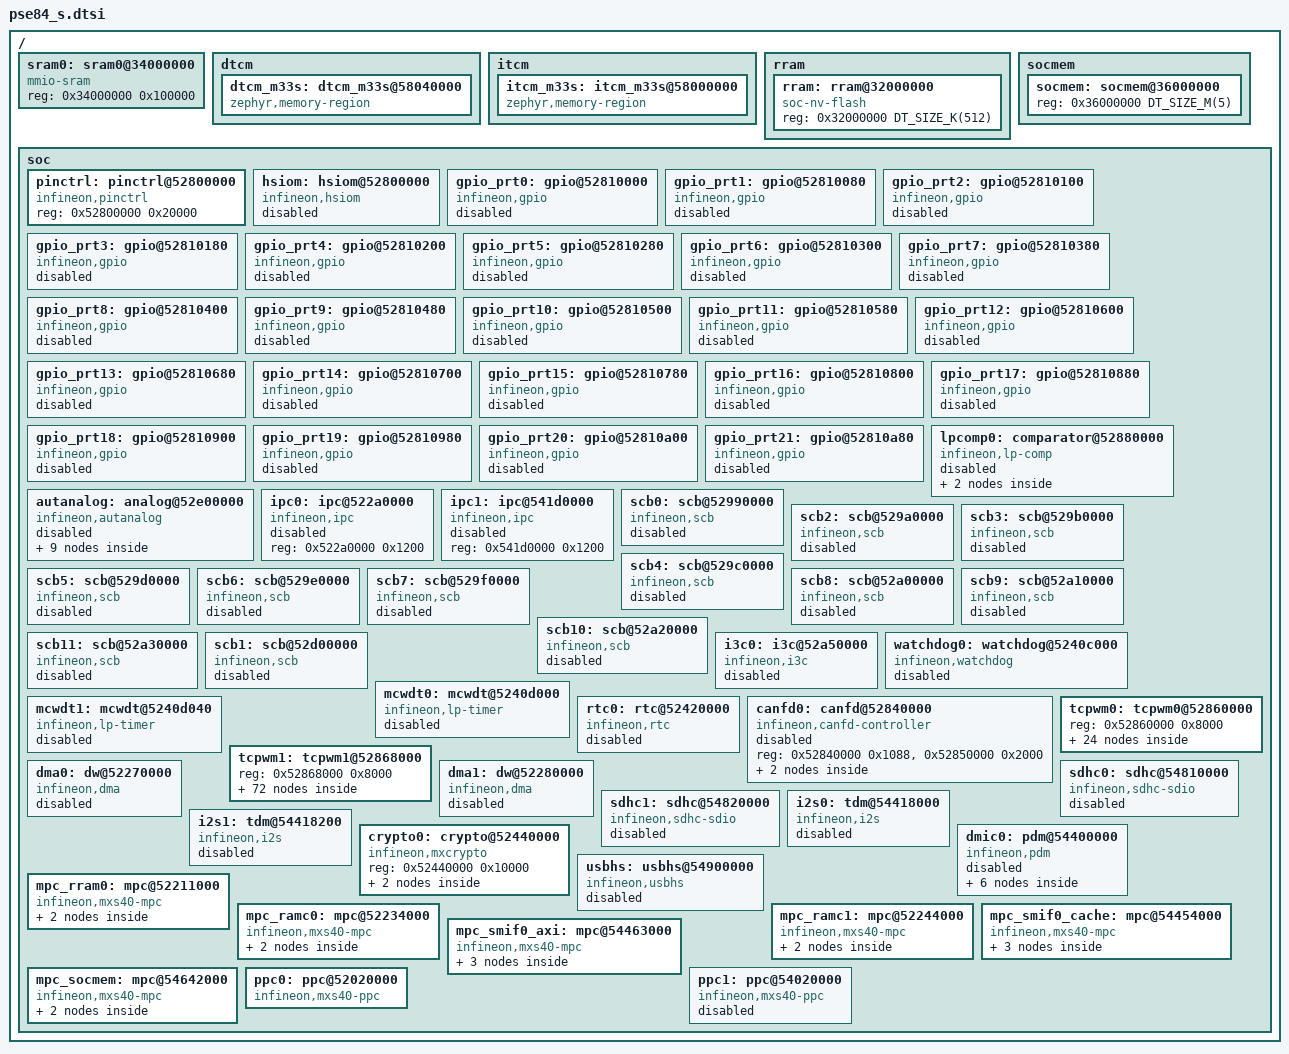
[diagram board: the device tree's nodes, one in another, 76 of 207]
/*
 * SPDX-FileCopyrightText: <text>Copyright (c) 2026 Infineon Technologies AG,
 * or an affiliate of Infineon Technologies AG. All rights reserved.</text>
 *
 * SPDX-License-Identifier: Apache-2.0
 */

#include <mem.h>
#include <zephyr/dt-bindings/ppc/infineon-edge-ppc.h>

/ {
	sram0: sram0@34000000 {
		compatible = "mmio-sram";
		reg = <0x34000000 0x100000>;
	};

	dtcm {
		#address-cells = <1>;
		#size-cells = <1>;

		dtcm_m33s: dtcm_m33s@58040000 {
			compatible = "zephyr,memory-region", "arm,dtcm";
			reg = <0x58040000 DT_SIZE_K(256)>;
			zephyr,memory-region = "DTCM";
		};
	};

	itcm {
		#address-cells = <1>;
		#size-cells = <1>;

		itcm_m33s: itcm_m33s@58000000 {
			compatible = "zephyr,memory-region", "arm,itcm";
			reg = <0x58000000 DT_SIZE_K(256)>;
			zephyr,memory-region = "ITCM";
		};
	};

	rram {
		#address-cells = <1>;
		#size-cells = <1>;

		rram: rram@32000000 {
			compatible = "soc-nv-flash";
			reg = <0x32000000 DT_SIZE_K(512)>;
		};
	};

	socmem {
		#address-cells = <1>;
		#size-cells = <1>;

		socmem: socmem@36000000 {
			reg = <0x36000000 DT_SIZE_M(5)>;
		};
	};

	soc {
		pinctrl: pinctrl@52800000 {
			compatible = "infineon,pinctrl";
			reg = <0x52800000 0x20000>;
		};

		hsiom: hsiom@52800000 {
			compatible = "infineon,hsiom";
			reg = <0x52800000 0x4000>;
			interrupts = <42 4>, <40 4>;
			status = "disabled";
		};

		gpio_prt0: gpio@52810000 {
			compatible = "infineon,gpio";
			reg = <0x52810000 0x80>;
			interrupts = <20 4>;
			gpio-controller;
			ngpios = <2>;
			status = "disabled";
			wakeup-source;
			#gpio-cells = <2>;
		};

		gpio_prt1: gpio@52810080 {
			compatible = "infineon,gpio";
			reg = <0x52810080 0x80>;
			gpio-controller;
			ngpios = <8>;
			status = "disabled";
			#gpio-cells = <2>;
		};

		gpio_prt2: gpio@52810100 {
			compatible = "infineon,gpio";
			reg = <0x52810100 0x80>;
			interrupts = <21 4>;
			gpio-controller;
			ngpios = <1>;
			status = "disabled";
			wakeup-source;
			#gpio-cells = <2>;
		};

		gpio_prt3: gpio@52810180 {
			compatible = "infineon,gpio";
			reg = <0x52810180 0x80>;
			interrupts = <22 4>;
			gpio-controller;
			ngpios = <2>;
			status = "disabled";
			wakeup-source;
			#gpio-cells = <2>;
		};

		gpio_prt4: gpio@52810200 {
			compatible = "infineon,gpio";
			reg = <0x52810200 0x80>;
			gpio-controller;
			ngpios = <8>;
			status = "disabled";
			#gpio-cells = <2>;
		};

		gpio_prt5: gpio@52810280 {
			compatible = "infineon,gpio";
			reg = <0x52810280 0x80>;
			interrupts = <23 4>;
			gpio-controller;
			ngpios = <1>;
			status = "disabled";
			wakeup-source;
			#gpio-cells = <2>;
		};

		gpio_prt6: gpio@52810300 {
			compatible = "infineon,gpio";
			reg = <0x52810300 0x80>;
			interrupts = <24 4>;
			gpio-controller;
			ngpios = <8>;
			status = "disabled";
			wakeup-source;
			#gpio-cells = <2>;
		};

		gpio_prt7: gpio@52810380 {
			compatible = "infineon,gpio";
			reg = <0x52810380 0x80>;
			interrupts = <25 4>;
			gpio-controller;
			ngpios = <8>;
			status = "disabled";
			wakeup-source;
			#gpio-cells = <2>;
		};

		gpio_prt8: gpio@52810400 {
			compatible = "infineon,gpio";
			reg = <0x52810400 0x80>;
			interrupts = <26 4>;
			gpio-controller;
			ngpios = <8>;
			status = "disabled";
			wakeup-source;
			#gpio-cells = <2>;
		};

		gpio_prt9: gpio@52810480 {
			compatible = "infineon,gpio";
			reg = <0x52810480 0x80>;
			interrupts = <27 4>;
			gpio-controller;
			ngpios = <4>;
			status = "disabled";
			wakeup-source;
			#gpio-cells = <2>;
		};

		gpio_prt10: gpio@52810500 {
			compatible = "infineon,gpio";
			reg = <0x52810500 0x80>;
			interrupts = <28 4>;
			gpio-controller;
			ngpios = <8>;
			status = "disabled";
			wakeup-source;
			#gpio-cells = <2>;
		};

		gpio_prt11: gpio@52810580 {
			compatible = "infineon,gpio";
			reg = <0x52810580 0x80>;
			interrupts = <29 4>;
			gpio-controller;
			ngpios = <8>;
			status = "disabled";
			wakeup-source;
			#gpio-cells = <2>;
		};

		gpio_prt12: gpio@52810600 {
			compatible = "infineon,gpio";
			reg = <0x52810600 0x80>;
			interrupts = <30 4>;
			gpio-controller;
			ngpios = <6>;
			status = "disabled";
			wakeup-source;
			#gpio-cells = <2>;
		};

		gpio_prt13: gpio@52810680 {
			compatible = "infineon,gpio";
			reg = <0x52810680 0x80>;
			interrupts = <31 4>;
			gpio-controller;
			ngpios = <8>;
			status = "disabled";
			wakeup-source;
			#gpio-cells = <2>;
		};

		gpio_prt14: gpio@52810700 {
			compatible = "infineon,gpio";
			reg = <0x52810700 0x80>;
			interrupts = <32 4>;
			gpio-controller;
			ngpios = <8>;
			status = "disabled";
			wakeup-source;
			#gpio-cells = <2>;
		};

		gpio_prt15: gpio@52810780 {
			compatible = "infineon,gpio";
			reg = <0x52810780 0x80>;
			interrupts = <33 4>;
			gpio-controller;
			ngpios = <8>;
			status = "disabled";
			wakeup-source;
			#gpio-cells = <2>;
		};

		gpio_prt16: gpio@52810800 {
			compatible = "infineon,gpio";
			reg = <0x52810800 0x80>;
			interrupts = <34 4>;
			gpio-controller;
			ngpios = <8>;
			status = "disabled";
			wakeup-source;
			#gpio-cells = <2>;
		};

		gpio_prt17: gpio@52810880 {
			compatible = "infineon,gpio";
			reg = <0x52810880 0x80>;
			interrupts = <35 4>;
			gpio-controller;
			ngpios = <8>;
			status = "disabled";
			wakeup-source;
			#gpio-cells = <2>;
		};

		gpio_prt18: gpio@52810900 {
			compatible = "infineon,gpio";
			reg = <0x52810900 0x80>;
			interrupts = <36 4>;
			gpio-controller;
			ngpios = <2>;
			status = "disabled";
			wakeup-source;
			#gpio-cells = <2>;
		};

		gpio_prt19: gpio@52810980 {
			compatible = "infineon,gpio";
			reg = <0x52810980 0x80>;
			interrupts = <37 4>;
			gpio-controller;
			ngpios = <2>;
			status = "disabled";
			wakeup-source;
			#gpio-cells = <2>;
		};

		gpio_prt20: gpio@52810a00 {
			compatible = "infineon,gpio";
			reg = <0x52810a00 0x80>;
			interrupts = <38 4>;
			gpio-controller;
			ngpios = <8>;
			status = "disabled";
			wakeup-source;
			#gpio-cells = <2>;
		};

		gpio_prt21: gpio@52810a80 {
			compatible = "infineon,gpio";
			reg = <0x52810a80 0x80>;
			interrupts = <39 4>;
			gpio-controller;
			ngpios = <8>;
			status = "disabled";
			wakeup-source;
			#gpio-cells = <2>;
		};

		lpcomp0: comparator@52880000 {
			compatible = "infineon,lp-comp";
			reg = <0x52880000 0x10000>;
			status = "disabled";
			wakeup-source;

			lpcomp0_0: lpcomp0-0 {
				compatible = "infineon,lp-comp-channel";
				channel = <0>;
				status = "disabled";
			};

			lpcomp0_1: lpcomp0-1 {
				compatible = "infineon,lp-comp-channel";
				channel = <1>;
				status = "disabled";
			};
		};

		autanalog: analog@52e00000 {
			compatible = "infineon,autanalog";
			reg = <0x52e00000 0x100000>;
			wakeup-source;
			interrupts = <57 4>, <58 4>;
			interrupt-names = "autanalog", "autanalog_fifo";
			status = "disabled";
			#address-cells = <1>;
			#size-cells = <1>;
			ranges;

			ctb0: ctb0@0 {
				compatible = "infineon,autanalog-ctb";
				reg = <0x0 0x1000>;
				status = "disabled";
				#address-cells = <1>;
				#size-cells = <0>;
			};

			ctb1: ctb1@10000 {
				compatible = "infineon,autanalog-ctb";
				reg = <0x10000 0x1000>;
				status = "disabled";
				#address-cells = <1>;
				#size-cells = <0>;
			};

			ptcomp0: ptcomp@e40000 {
				compatible = "infineon,autanalog-ptcomp";
				reg = <0xe40000 0xf00>;
				status = "disabled";
				#address-cells = <1>;
				#size-cells = <0>;
			};

			dac0: dac0@60000 {
				compatible = "infineon,autanalog-ctdac";
				reg = <0x60000 0x1000>;
				clk-dst = <0x200>;
				status = "disabled";
				#io-channel-cells = <1>;
				#address-cells = <1>;
				#size-cells = <0>;

				/* FW channel (default) */
				channel@f {
					reg = <15>;
					zephyr,resolution = <12>;
				};
			};

			dac1: dac1@70000 {
				compatible = "infineon,autanalog-ctdac";
				reg = <0x70000 0x1000>;
				clk-dst = <0x201>;
				status = "disabled";
				#io-channel-cells = <1>;
				#address-cells = <1>;
				#size-cells = <0>;

				/* FW channel (default): direct value writes via Zephyr DAC API */
				channel@f {
					reg = <15>;
					zephyr,resolution = <12>;
				};
			};

			adc0: adc0@80000 {
				compatible = "infineon,autanalog-sar-adc";
				/* Offset within AutAnalog subsystem */
				reg = <0x80000 0xf20>;
				status = "disabled";
				#io-channel-cells = <1>;
			};

			prb0: prb@e0300 {
				compatible = "infineon,autanalog-prb";
				reg = <0xe0300 0x100>;
				status = "disabled";
				#address-cells = <1>;
				#size-cells = <0>;
			};
		};

		ipc0: ipc@522a0000 {
			compatible = "infineon,ipc";
			reg = <0x522a0000 0x1200>;
			status = "disabled";
			#ipc-config-cells = <3>;
		};

		ipc1: ipc@541d0000 {
			compatible = "infineon,ipc";
			reg = <0x541d0000 0x1200>;
			status = "disabled";
			#ipc-config-cells = <3>;
		};

		scb0: scb@52990000 {
			compatible = "infineon,scb";
			reg = <0x52990000 0xfd0>;
			interrupts = <43 4>;
			clk-dst = <0x100>;
			status = "disabled";
			wakeup-source;
		};

		scb2: scb@529a0000 {
			compatible = "infineon,scb";
			reg = <0x529a0000 0xfd0>;
			interrupts = <143 4>;
			clk-dst = <0x101>;
			status = "disabled";
		};

		scb3: scb@529b0000 {
			compatible = "infineon,scb";
			reg = <0x529b0000 0xfd0>;
			interrupts = <144 4>;
			clk-dst = <0x102>;
			status = "disabled";
		};

		scb4: scb@529c0000 {
			compatible = "infineon,scb";
			reg = <0x529c0000 0xfd0>;
			interrupts = <145 4>;
			clk-dst = <0x103>;
			status = "disabled";
		};

		scb5: scb@529d0000 {
			compatible = "infineon,scb";
			reg = <0x529d0000 0xfd0>;
			interrupts = <146 4>;
			clk-dst = <0x104>;
			status = "disabled";
		};

		scb6: scb@529e0000 {
			compatible = "infineon,scb";
			reg = <0x529e0000 0xfd0>;
			interrupts = <147 4>;
			clk-dst = <0x105>;
			status = "disabled";
		};

		scb7: scb@529f0000 {
			compatible = "infineon,scb";
			reg = <0x529f0000 0xfd0>;
			interrupts = <148 4>;
			clk-dst = <0x106>;
			status = "disabled";
		};

		scb8: scb@52a00000 {
			compatible = "infineon,scb";
			reg = <0x52a00000 0xfd0>;
			interrupts = <149 4>;
			clk-dst = <0x107>;
			status = "disabled";
		};

		scb9: scb@52a10000 {
			compatible = "infineon,scb";
			reg = <0x52a10000 0xfd0>;
			interrupts = <150 4>;
			clk-dst = <0x108>;
			status = "disabled";
		};

		scb10: scb@52a20000 {
			compatible = "infineon,scb";
			reg = <0x52a20000 0xfd0>;
			interrupts = <151 4>;
			clk-dst = <0x109>;
			status = "disabled";
		};

		scb11: scb@52a30000 {
			compatible = "infineon,scb";
			reg = <0x52a30000 0xfd0>;
			interrupts = <152 4>;
			clk-dst = <0x10a>;
			status = "disabled";
		};

		scb1: scb@52d00000 {
			compatible = "infineon,scb";
			reg = <0x52d00000 0xfd0>;
			interrupts = <142 4>;
			clk-dst = <0x800>;
			status = "disabled";
		};

		i3c0: i3c@52a50000 {
			compatible = "infineon,i3c";
			reg = <0x52a50000 0x438>;
			interrupts = <176 4>;
			status = "disabled";
		};

		watchdog0: watchdog@5240c000 {
			compatible = "infineon,watchdog";
			reg = <0x5240c000 0x180>;
			interrupts = <54 4>;
			status = "disabled";
			wakeup-source;
		};

		mcwdt0: mcwdt@5240d000 {
			compatible = "infineon,lp-timer";
			reg = <0x5240d000 0x40>;
			interrupts = <55 4>;
			status = "disabled";
			wakeup-source;
		};

		mcwdt1: mcwdt@5240d040 {
			compatible = "infineon,lp-timer";
			reg = <0x5240d040 0x40>;
			interrupts = <0 4>;
			status = "disabled";
			wakeup-source;
		};

		rtc0: rtc@52420000 {
			compatible = "infineon,rtc";
			reg = <0x52420000 0x1140>;
			interrupts = <56 4>;
			alarms-count = <2>;
			status = "disabled";
			wakeup-source;
		};

		canfd0: canfd@52840000 {
			compatible = "infineon,canfd-controller";
			reg = <0x52840000 0x1088>, <0x52850000 0x2000>;
			reg-names = "wrapper", "mram";
			#address-cells = <1>;
			#size-cells = <1>;
			ranges;
			status = "disabled";

			can0: can@52840000 {
				compatible = "infineon,can";
				reg = <0x52840000 0x200>, <0x52850000 0x1000>;
				reg-names = "m_can", "message_ram";
				clk-dst = <0x10b>;
				status = "disabled";
				bosch,mram-cfg = <0x0 15 15 16 0 0 15 15>;
				interrupts = <106 4>, <107 4>;
				interrupt-names = "int0", "int1";
			};

			can1: can@52840200 {
				compatible = "infineon,can";
				reg = <0x52840200 0x200>, <0x52850000 0x2000>;
				reg-names = "m_can", "message_ram";
				clk-dst = <0x10c>;
				status = "disabled";
				bosch,mram-cfg = <0x1000 15 15 16 0 0 15 15>;
				interrupts = <108 4>, <109 4>;
				interrupt-names = "int0", "int1";
			};
		};

		tcpwm0: tcpwm0@52860000 {
			reg = <0x52860000 0x8000>;
			#address-cells = <1>;
			#size-cells = <1>;

			tcpwm0_0: tcpwm0_0@52860000 {
				compatible = "infineon,tcpwm";
				reg = <0x52860000 0x80>;
				interrupts = <110 4>;
				resolution = <32>;
				clk-dst = <0x10d>;
				status = "disabled";

				pwm0_0: pwm0_0 {
					compatible = "infineon,tcpwm-pwm";
					#pwm-cells = <3>;
					status = "disabled";
				};

				counter0_0: counter0_0 {
					compatible = "infineon,tcpwm-counter";
					status = "disabled";
				};
			};

			tcpwm0_1: tcpwm0_1@52860080 {
				compatible = "infineon,tcpwm";
				reg = <0x52860080 0x80>;
				interrupts = <111 4>;
				resolution = <32>;
				clk-dst = <0x10e>;
				status = "disabled";

				pwm0_1: pwm0_1 {
					compatible = "infineon,tcpwm-pwm";
					#pwm-cells = <3>;
					status = "disabled";
				};

				counter0_1: counter0_1 {
					compatible = "infineon,tcpwm-counter";
					status = "disabled";
				};
			};

			tcpwm0_2: tcpwm0_2@52860100 {
				compatible = "infineon,tcpwm";
				reg = <0x52860100 0x80>;
				interrupts = <112 4>;
				resolution = <32>;
				clk-dst = <0x10f>;
				status = "disabled";

				pwm0_2: pwm0_2 {
					compatible = "infineon,tcpwm-pwm";
					#pwm-cells = <3>;
					status = "disabled";
				};

				counter0_2: counter0_2 {
					compatible = "infineon,tcpwm-counter";
					status = "disabled";
				};
			};

			tcpwm0_3: tcpwm0_3@52860180 {
				compatible = "infineon,tcpwm";
				reg = <0x52860180 0x80>;
				interrupts = <113 4>;
				resolution = <32>;
				clk-dst = <0x110>;
				status = "disabled";

				pwm0_3: pwm0_3 {
					compatible = "infineon,tcpwm-pwm";
					#pwm-cells = <3>;
					status = "disabled";
				};

				counter0_3: counter0_3 {
					compatible = "infineon,tcpwm-counter";
					status = "disabled";
				};
			};

			tcpwm0_4: tcpwm0_4@52860200 {
				compatible = "infineon,tcpwm";
				reg = <0x52860200 0x80>;
				interrupts = <114 4>;
				resolution = <32>;
				clk-dst = <0x111>;
				status = "disabled";

				pwm0_4: pwm0_4 {
					compatible = "infineon,tcpwm-pwm";
					#pwm-cells = <3>;
					status = "disabled";
				};

				counter0_4: counter0_4 {
					compatible = "infineon,tcpwm-counter";
					status = "disabled";
				};
			};

			tcpwm0_5: tcpwm0_5@52860280 {
				compatible = "infineon,tcpwm";
				reg = <0x52860280 0x80>;
				interrupts = <115 4>;
				resolution = <32>;
				clk-dst = <0x112>;
				status = "disabled";

				pwm0_5: pwm0_5 {
					compatible = "infineon,tcpwm-pwm";
					#pwm-cells = <3>;
					status = "disabled";
				};

				counter0_5: counter0_5 {
					compatible = "infineon,tcpwm-counter";
					status = "disabled";
				};
			};

			tcpwm0_6: tcpwm0_6@52860300 {
				compatible = "infineon,tcpwm";
				reg = <0x52860300 0x80>;
				interrupts = <116 4>;
				resolution = <32>;
				clk-dst = <0x113>;
				status = "disabled";

				pwm0_6: pwm0_6 {
					compatible = "infineon,tcpwm-pwm";
					#pwm-cells = <3>;
					status = "disabled";
				};

				counter0_6: counter0_6 {
					compatible = "infineon,tcpwm-counter";
					status = "disabled";
				};
			};

			tcpwm0_7: tcpwm0_7@52860380 {
				compatible = "infineon,tcpwm";
				reg = <0x52860380 0x80>;
				interrupts = <117 4>;
				resolution = <32>;
				clk-dst = <0x114>;
				status = "disabled";

				pwm0_7: pwm0_7 {
					compatible = "infineon,tcpwm-pwm";
					#pwm-cells = <3>;
					status = "disabled";
				};

				counter0_7: counter0_7 {
					compatible = "infineon,tcpwm-counter";
					status = "disabled";
				};
			};
		};

		tcpwm1: tcpwm1@52868000 {
			reg = <0x52868000 0x8000>;
			#address-cells = <1>;
			#size-cells = <1>;

			tcpwm1_0: tcpwm1_0@52868000 {
				compatible = "infineon,tcpwm";
				reg = <0x52868000 0x80>;
				interrupts = <118 4>;
				resolution = <16>;
				clk-dst = <0x115>;
				status = "disabled";

				pwm1_0: pwm1_0 {
					compatible = "infineon,tcpwm-pwm";
					#pwm-cells = <3>;
					status = "disabled";
				};

				counter1_0: counter1_0 {
					compatible = "infineon,tcpwm-counter";
					status = "disabled";
				};
			};

			tcpwm1_1: tcpwm1_1@52868080 {
				compatible = "infineon,tcpwm";
				reg = <0x52868080 0x80>;
				interrupts = <119 4>;
				resolution = <16>;
				clk-dst = <0x116>;
				status = "disabled";

				pwm1_1: pwm1_1 {
					compatible = "infineon,tcpwm-pwm";
					#pwm-cells = <3>;
					status = "disabled";
				};

				counter1_1: counter1_1 {
					compatible = "infineon,tcpwm-counter";
					status = "disabled";
				};
			};

			tcpwm1_2: tcpwm1_2@52868100 {
				compatible = "infineon,tcpwm";
				reg = <0x52868100 0x80>;
				interrupts = <120 4>;
				resolution = <16>;
				clk-dst = <0x117>;
				status = "disabled";

				pwm1_2: pwm1_2 {
					compatible = "infineon,tcpwm-pwm";
					#pwm-cells = <3>;
					status = "disabled";
				};

				counter1_2: counter1_2 {
					compatible = "infineon,tcpwm-counter";
					status = "disabled";
				};
			};

			tcpwm1_3: tcpwm1_3@52868180 {
				compatible = "infineon,tcpwm";
				reg = <0x52868180 0x80>;
				interrupts = <121 4>;
				resolution = <16>;
				clk-dst = <0x118>;
				status = "disabled";

				pwm1_3: pwm1_3 {
					compatible = "infineon,tcpwm-pwm";
					#pwm-cells = <3>;
					status = "disabled";
				};

				counter1_3: counter1_3 {
					compatible = "infineon,tcpwm-counter";
					status = "disabled";
				};
			};

			tcpwm1_4: tcpwm1_4@52868200 {
				compatible = "infineon,tcpwm";
				reg = <0x52868200 0x80>;
				interrupts = <122 4>;
				resolution = <16>;
				clk-dst = <0x119>;
				status = "disabled";

				pwm1_4: pwm1_4 {
					compatible = "infineon,tcpwm-pwm";
					#pwm-cells = <3>;
					status = "disabled";
				};

				counter1_4: counter1_4 {
					compatible = "infineon,tcpwm-counter";
					status = "disabled";
				};
			};

			tcpwm1_5: tcpwm1_5@52868280 {
				compatible = "infineon,tcpwm";
				reg = <0x52868280 0x80>;
				interrupts = <123 4>;
				resolution = <16>;
				clk-dst = <0x11a>;
				status = "disabled";

				pwm1_5: pwm1_5 {
					compatible = "infineon,tcpwm-pwm";
					#pwm-cells = <3>;
					status = "disabled";
				};

				counter1_5: counter1_5 {
					compatible = "infineon,tcpwm-counter";
					status = "disabled";
				};
			};

			tcpwm1_6: tcpwm1_6@52868300 {
				compatible = "infineon,tcpwm";
				reg = <0x52868300 0x80>;
				interrupts = <124 4>;
				resolution = <16>;
				clk-dst = <0x11b>;
				status = "disabled";

				pwm1_6: pwm1_6 {
					compatible = "infineon,tcpwm-pwm";
					#pwm-cells = <3>;
					status = "disabled";
				};

				counter1_6: counter1_6 {
					compatible = "infineon,tcpwm-counter";
					status = "disabled";
				};
			};

			tcpwm1_7: tcpwm1_7@52868380 {
				compatible = "infineon,tcpwm";
				reg = <0x52868380 0x80>;
				interrupts = <125 4>;
				resolution = <16>;
				clk-dst = <0x11c>;
				status = "disabled";

				pwm1_7: pwm1_7 {
					compatible = "infineon,tcpwm-pwm";
					#pwm-cells = <3>;
					status = "disabled";
				};

				counter1_7: counter1_7 {
					compatible = "infineon,tcpwm-counter";
					status = "disabled";
				};
			};

			tcpwm1_8: tcpwm1_8@52868400 {
				compatible = "infineon,tcpwm";
				reg = <0x52868400 0x80>;
				interrupts = <126 4>;
				resolution = <16>;
				clk-dst = <0x11d>;
				status = "disabled";

				pwm1_8: pwm1_8 {
					compatible = "infineon,tcpwm-pwm";
					#pwm-cells = <3>;
					status = "disabled";
				};

				counter1_8: counter1_8 {
					compatible = "infineon,tcpwm-counter";
					status = "disabled";
				};
			};

			tcpwm1_9: tcpwm1_9@52868480 {
				compatible = "infineon,tcpwm";
				reg = <0x52868480 0x80>;
				interrupts = <127 4>;
				resolution = <16>;
				clk-dst = <0x11e>;
				status = "disabled";

				pwm1_9: pwm1_9 {
					compatible = "infineon,tcpwm-pwm";
					#pwm-cells = <3>;
					status = "disabled";
				};

				counter1_9: counter1_9 {
					compatible = "infineon,tcpwm-counter";
					status = "disabled";
				};
			};

			tcpwm1_10: tcpwm1_10@52868500 {
				compatible = "infineon,tcpwm";
				reg = <0x52868500 0x80>;
				interrupts = <128 4>;
				resolution = <16>;
				clk-dst = <0x11f>;
				status = "disabled";

				pwm1_10: pwm1_10 {
					compatible = "infineon,tcpwm-pwm";
					#pwm-cells = <3>;
					status = "disabled";
				};

				counter1_10: counter1_10 {
					compatible = "infineon,tcpwm-counter";
					status = "disabled";
				};
			};

			tcpwm1_11: tcpwm1_11@52868580 {
				compatible = "infineon,tcpwm";
				reg = <0x52868580 0x80>;
				interrupts = <129 4>;
				resolution = <16>;
				clk-dst = <0x120>;
				status = "disabled";

				pwm1_11: pwm1_11 {
					compatible = "infineon,tcpwm-pwm";
					#pwm-cells = <3>;
					status = "disabled";
				};

				counter1_11: counter1_11 {
					compatible = "infineon,tcpwm-counter";
					status = "disabled";
				};
			};

			tcpwm1_12: tcpwm1_12@52868600 {
				compatible = "infineon,tcpwm";
				reg = <0x52868600 0x80>;
				interrupts = <130 4>;
				resolution = <16>;
				clk-dst = <0x121>;
				status = "disabled";

				pwm1_12: pwm1_12 {
					compatible = "infineon,tcpwm-pwm";
					#pwm-cells = <3>;
					status = "disabled";
				};

				counter1_12: counter1_12 {
					compatible = "infineon,tcpwm-counter";
					status = "disabled";
				};
			};

			tcpwm1_13: tcpwm1_13@52868680 {
				compatible = "infineon,tcpwm";
				reg = <0x52868680 0x80>;
				interrupts = <131 4>;
				resolution = <16>;
				clk-dst = <0x122>;
				status = "disabled";

				pwm1_13: pwm1_13 {
					compatible = "infineon,tcpwm-pwm";
					#pwm-cells = <3>;
					status = "disabled";
				};

				counter1_13: counter1_13 {
					compatible = "infineon,tcpwm-counter";
					status = "disabled";
				};
			};

			tcpwm1_14: tcpwm1_14@52868700 {
				compatible = "infineon,tcpwm";
				reg = <0x52868700 0x80>;
				interrupts = <132 4>;
				resolution = <16>;
				clk-dst = <0x123>;
				status = "disabled";

				pwm1_14: pwm1_14 {
					compatible = "infineon,tcpwm-pwm";
					#pwm-cells = <3>;
					status = "disabled";
				};

				counter1_14: counter1_14 {
					compatible = "infineon,tcpwm-counter";
					status = "disabled";
				};
			};

			tcpwm1_15: tcpwm1_15@52868780 {
				compatible = "infineon,tcpwm";
				reg = <0x52868780 0x80>;
				interrupts = <133 4>;
				resolution = <16>;
				clk-dst = <0x124>;
				status = "disabled";

				pwm1_15: pwm1_15 {
					compatible = "infineon,tcpwm-pwm";
					#pwm-cells = <3>;
					status = "disabled";
				};

				counter1_15: counter1_15 {
					compatible = "infineon,tcpwm-counter";
					status = "disabled";
				};
			};

			tcpwm1_16: tcpwm1_16@52868800 {
				compatible = "infineon,tcpwm";
				reg = <0x52868800 0x80>;
				interrupts = <134 4>;
				resolution = <16>;
				clk-dst = <0x125>;
				status = "disabled";

				pwm1_16: pwm1_16 {
					compatible = "infineon,tcpwm-pwm";
					#pwm-cells = <3>;
					status = "disabled";
				};

				counter1_16: counter1_16 {
					compatible = "infineon,tcpwm-counter";
					status = "disabled";
				};
			};

			tcpwm1_17: tcpwm1_17@52868880 {
				compatible = "infineon,tcpwm";
				reg = <0x52868880 0x80>;
				interrupts = <135 4>;
				resolution = <16>;
				clk-dst = <0x126>;
				status = "disabled";

				pwm1_17: pwm1_17 {
					compatible = "infineon,tcpwm-pwm";
					#pwm-cells = <3>;
					status = "disabled";
				};

				counter1_17: counter1_17 {
					compatible = "infineon,tcpwm-counter";
					status = "disabled";
				};
			};

			tcpwm1_18: tcpwm1_18@52868900 {
				compatible = "infineon,tcpwm";
				reg = <0x52868900 0x80>;
				interrupts = <136 4>;
				resolution = <16>;
				clk-dst = <0x127>;
				status = "disabled";

				pwm1_18: pwm1_18 {
					compatible = "infineon,tcpwm-pwm";
					#pwm-cells = <3>;
					status = "disabled";
				};

				counter1_18: counter1_18 {
					compatible = "infineon,tcpwm-counter";
					status = "disabled";
				};
			};

			tcpwm1_19: tcpwm1_19@52868980 {
				compatible = "infineon,tcpwm";
				reg = <0x52868980 0x80>;
				interrupts = <137 4>;
				resolution = <16>;
				clk-dst = <0x128>;
				status = "disabled";

				pwm1_19: pwm1_19 {
					compatible = "infineon,tcpwm-pwm";
					#pwm-cells = <3>;
					status = "disabled";
				};

				counter1_19: counter1_19 {
					compatible = "infineon,tcpwm-counter";
					status = "disabled";
				};
			};

			tcpwm1_20: tcpwm1_20@52868a00 {
				compatible = "infineon,tcpwm";
				reg = <0x52868a00 0x80>;
				interrupts = <138 4>;
				resolution = <16>;
				clk-dst = <0x129>;
				status = "disabled";

				pwm1_20: pwm1_20 {
					compatible = "infineon,tcpwm-pwm";
					#pwm-cells = <3>;
					status = "disabled";
				};

				counter1_20: counter1_20 {
					compatible = "infineon,tcpwm-counter";
					status = "disabled";
				};
			};

			tcpwm1_21: tcpwm1_21@52868a80 {
				compatible = "infineon,tcpwm";
				reg = <0x52868a80 0x80>;
				interrupts = <139 4>;
				resolution = <16>;
				clk-dst = <0x12a>;
				status = "disabled";

				pwm1_21: pwm1_21 {
					compatible = "infineon,tcpwm-pwm";
					#pwm-cells = <3>;
					status = "disabled";
				};

				counter1_21: counter1_21 {
					compatible = "infineon,tcpwm-counter";
					status = "disabled";
				};
			};

			tcpwm1_22: tcpwm1_22@52868b00 {
				compatible = "infineon,tcpwm";
				reg = <0x52868b00 0x80>;
				interrupts = <140 4>;
				resolution = <16>;
				clk-dst = <0x12b>;
				status = "disabled";

				pwm1_22: pwm1_22 {
					compatible = "infineon,tcpwm-pwm";
					#pwm-cells = <3>;
					status = "disabled";
				};

				counter1_22: counter1_22 {
					compatible = "infineon,tcpwm-counter";
					status = "disabled";
				};
			};

			tcpwm1_23: tcpwm1_23@52868b80 {
				compatible = "infineon,tcpwm";
				reg = <0x52868b80 0x80>;
				interrupts = <141 4>;
				resolution = <16>;
				clk-dst = <0x12c>;
				status = "disabled";

				pwm1_23: pwm1_23 {
					compatible = "infineon,tcpwm-pwm";
					#pwm-cells = <3>;
					status = "disabled";
				};

				counter1_23: counter1_23 {
					compatible = "infineon,tcpwm-counter";
					status = "disabled";
				};
			};
		};

		dma0: dw@52270000 {
			#dma-cells = <1>;
			compatible = "infineon,dma";
			reg = <0x52270000 0x10000>;
			dma-channels = <16>;
			interrupts = <82 4>, /* CH0 */
				     <83 4>, /* CH1 */
				     <84 4>, /* CH2 */
				     <85 4>, /* CH3 */
				     <86 4>, /* CH4 */
				     <87 4>, /* CH5 */
				     <88 4>, /* CH6 */
				     <89 4>, /* CH7 */
				     <90 4>, /* CH8 */
				     <91 4>, /* CH9 */
				     <92 4>, /* CH10 */
				     <93 4>, /* CH11 */
				     <94 4>, /* CH12 */
				     <95 4>, /* CH13 */
				     <96 4>, /* CH14 */
				     <97 4>; /* CH15 */
			status = "disabled";
		};

		dma1: dw@52280000 {
			#dma-cells = <1>;
			compatible = "infineon,dma";
			reg = <0x52280000 0x10000>;
			dma-channels = <16>;
			interrupts = <181 4>, /* CH0 */
				     <182 4>, /* CH1 */
				     <183 4>, /* CH2 */
				     <184 4>, /* CH3 */
				     <185 4>, /* CH4 */
				     <186 4>, /* CH5 */
				     <187 4>, /* CH6 */
				     <188 4>, /* CH7 */
				     <189 4>, /* CH8 */
				     <190 4>, /* CH9 */
				     <191 4>, /* CH10 */
				     <192 4>, /* CH11 */
				     <193 4>, /* CH12 */
				     <194 4>, /* CH13 */
				     <195 4>, /* CH14 */
				     <196 4>; /* CH15 */
			status = "disabled";
		};

		sdhc0: sdhc@54810000 {
			compatible = "infineon,sdhc-sdio";
			reg = <0x54810000 0x2000>;
			interrupts = <155 4>, /* SDIO wakeup interrupt for mxsdhc */
				     <154 6>; /* Consolidated interrupt for mxsdhc */
			clk-dst = <0x10200>;
			status = "disabled";
		};

		sdhc1: sdhc@54820000 {
			compatible = "infineon,sdhc-sdio";
			reg = <0x54820000 0x2000>;
			interrupts = <157 4>, /* SDIO wakeup interrupt for mxsdhc */
				     <156 6>; /* Consolidated interrupt for mxsdhc */
			clk-dst = <0x10300>;
			status = "disabled";
		};

		i2s0: tdm@54418000 {
			#address-cells = <1>;
			#size-cells = <0>;
			compatible = "infineon,i2s";
			reg = <0x54418000 0x200>;
			interrupts = <158 4>, /* RX Structure */
				     <159 4>; /* TX Structure */
			clk-dst = <0x00010100>;
			status = "disabled";
		};

		i2s1: tdm@54418200 {
			#address-cells = <1>;
			#size-cells = <0>;
			compatible = "infineon,i2s";
			reg = <0x54418200 0x200>;
			interrupts = <160 4>, /* RX Structure */
				     <161 4>; /* TX Structure */
			clk-dst = <0x00010101>;
			status = "disabled";
		};

		crypto0: crypto@52440000 {
			compatible = "infineon,mxcrypto";
			reg = <0x52440000 0x10000>;

			mxcrypto_trng: mxcrypto_trng {
				compatible = "infineon,mxcrypto-trng";
				status = "disabled";
			};

			mxcrypto_crypto: mxcrypto_crypto {
				compatible = "infineon,mxcrypto-crypto";
				status = "disabled";
			};
		};

		dmic0: pdm@54400000 {
			#address-cells = <1>;
			#size-cells = <0>;
			compatible = "infineon,pdm";
			reg = <0x54400000 0x8800>;
			interrupts = <165 4>, /* Channel 0 */
				     <166 4>, /* Channel 1 */
				     <167 4>, /* Channel 2 */
				     <168 4>, /* Channel 3 */
				     <169 4>, /* Channel 4 */
				     <170 4>; /* Channel 5 */
			clk-dst = <0x00010102>;
			status = "disabled";

			dmic0_ch0: channel@54408000 {
				reg = <0x54408000 0x100>;
				channel = <0>;
				status = "disabled";
			};

			dmic0_ch1: channel@54408100 {
				reg = <0x54408100 0x100>;
				channel = <1>;
				status = "disabled";
			};

			dmic0_ch2: channel@54408200 {
				reg = <0x54408200 0x100>;
				channel = <2>;
				status = "disabled";
			};

			dmic0_ch3: channel@54408300 {
				reg = <0x54408300 0x100>;
				channel = <3>;
				status = "disabled";
			};

			dmic0_ch4: channel@54408400 {
				reg = <0x54408400 0x100>;
				channel = <4>;
				status = "disabled";
			};

			dmic0_ch5: channel@54408500 {
				reg = <0x54408500 0x100>;
				channel = <5>;
				status = "disabled";
			};
		};

		usbhs: usbhs@54900000 {
			compatible = "infineon,usbhs", "snps,dwc2";
			reg = <0x54900000 0x40100>;
			interrupts = <174 4>, /* usbhs_ctrl_irqn */
				     <175 4>; /* usbhss_irqn */
			num-in-eps = <9>;
			num-out-eps = <9>;
			ghwcfg1 = <0x00000000>;
			ghwcfg2 = <0x228fe052>;
			ghwcfg4 = <0xe2103a20>;
			status = "disabled";
			mmio-peri-inst = <1>;
			mmio-peri-group = <3>;
			mmio-reg-bit-pos = <5>;
			mmio-peri-hf-src = <1>;
			mmio-peri-div = <3>;
		};

		/*
		 * Memory Protection Controllers (MPC)
		 *
		 * Each node covers one MPC hardware block. Child nodes describe
		 * the (offset, size) ranges within the controlled memory, with
		 * pc-configs listing the (pc, secure, access) 3-tuples that
		 * govern which protection contexts may access each range.
		 *
		 * A "pc" (protection context) is the identity of a bus master: the
		 * MPC grants that master access to the region.  On PSE84:
		 *   PC2 = CM33 Secure, PC5 = CM33 Non-Secure, PC6 = CM55,
		 *   PC7 = debug/DAP.  (The "M33_M55" non-secure domain uses
		 *   pc-mask 0xE6 = PC1,2,5,6,7.)
		 *
		 * pc-configs encoding (per cy_stc_mpc_rot_cfg_t):
		 *   pc     : 2, 5, 6, or 7 (see above)
		 *   secure : 0 = Secure,  1 = Non-Secure  (cy_en_mpc_sec_attr_t)
		 *   access : 0 = none, 1 = R, 2 = W, 3 = RW  (cy_en_mpc_access_attr_t)
		 */

		/* RRAMC0 MPC - RRAM requires separate SROM-level init; skip all auto-config */
		mpc_rram0: mpc@52211000 {
			compatible = "infineon,mxs40-mpc";
			reg = <0x52211000 0x1000>;
			skip-auto-config;
			#address-cells = <1>;
			#size-cells = <1>;
			status = "okay";

			/* M33-S: PC2/PC7 Secure RW */
			region@11000 {
				reg = <0x00011000 0x0004A000>;
				pc-configs = <2 0 3  7 0 3>;
			};

			/* M33-M55 shared: PC2/PC5/PC6/PC7 Non-Secure RW */
			region@5b000 {
				reg = <0x0005B000 0x00008000>;
				pc-configs = <2 1 3  5 1 3  6 1 3  7 1 3>;
			};
		};

		/* RAMC0 MPC - SRAM bank 0 */
		mpc_ramc0: mpc@52234000 {
			compatible = "infineon,mxs40-mpc";
			reg = <0x52234000 0x1000>;
			violation-response = "bus-error";
			#address-cells = <1>;
			#size-cells = <1>;
			status = "okay";

			/* M33-S: PC2/PC7 Secure RW */
			region@1000 {
				reg = <0x00001000 0x00057000>;
				pc-configs = <2 0 3  7 0 3>;
			};

			/* M33-NS: PC2/PC5/PC7 Non-Secure RW */
			region@58000 {
				reg = <0x00058000 0x00028000>;
				pc-configs = <2 1 3  5 1 3  7 1 3>;
			};
		};

		/* RAMC1 MPC - SRAM bank 1 */
		mpc_ramc1: mpc@52244000 {
			compatible = "infineon,mxs40-mpc";
			reg = <0x52244000 0x1000>;
			violation-response = "bus-error";
			#address-cells = <1>;
			#size-cells = <1>;
			status = "okay";

			/* M33-NS: PC2/PC5/PC7 Non-Secure RW */
			region@0 {
				reg = <0x00000000 0x0003D000>;
				pc-configs = <2 1 3  5 1 3  7 1 3>;
			};

			/* M33-M55 shared: PC2/PC5/PC6/PC7 Non-Secure RW */
			region@3d000 {
				reg = <0x0003D000 0x00043000>;
				pc-configs = <2 1 3  5 1 3  6 1 3  7 1 3>;
			};
		};

		/*
		 * SMIF0 cache AHB MPC - external flash cache path.
		 * SMIF0 has two MPCs; the names mirror the hardware blocks:
		 *   mpc_smif0_cache = SMIF0_CACHE_BLOCK_CACHEBLK_AHB_MPC0 @ 0x54454000
		 *   mpc_smif0_axi   = SMIF0_CORE_AXI_MPC0               @ 0x54463000
		 */
		mpc_smif0_cache: mpc@54454000 {
			compatible = "infineon,mxs40-mpc";
			reg = <0x54454000 0x1000>;
			violation-response = "bus-error";
			#address-cells = <1>;
			#size-cells = <1>;
			status = "okay";

			/* M33-S: PC2/PC7 Secure RW */
			region@100000 {
				reg = <0x00100000 0x00200000>;
				pc-configs = <2 0 3  7 0 3>;
			};

			/* M33-NS: PC2/PC5/PC7 Non-Secure RW.
			 * bus-nonsecure marks these blocks Non-Secure in the
			 * non-ROT (IDAU/BXNS) security-attribute LUT so the NS
			 * image in this flash is reachable from the NS world.
			 */
			region@300000 {
				reg = <0x00300000 0x00240000>;
				pc-configs = <2 1 3  5 1 3  7 1 3>;
				bus-nonsecure;
			};

			/* M55: PC2/PC6/PC7 Non-Secure RW */
			region@500000 {
				reg = <0x00500000 0x00300000>;
				pc-configs = <2 1 3  6 1 3  7 1 3>;
			};
		};

		/* SMIF0 core AXI MPC - external flash AXI path */
		mpc_smif0_axi: mpc@54463000 {
			compatible = "infineon,mxs40-mpc";
			reg = <0x54463000 0x1000>;
			violation-response = "bus-error";
			#address-cells = <1>;
			#size-cells = <1>;
			status = "okay";

			/* M33-S: PC2/PC7 Secure RW */
			region@100000 {
				reg = <0x00100000 0x00200000>;
				pc-configs = <2 0 3  7 0 3>;
			};

			/* M33-NS: PC2/PC5/PC7 Non-Secure RW */
			region@300000 {
				reg = <0x00300000 0x00240000>;
				pc-configs = <2 1 3  5 1 3  7 1 3>;
			};

			/* M55: PC2/PC6/PC7 Non-Secure RW */
			region@500000 {
				reg = <0x00500000 0x00300000>;
				pc-configs = <2 1 3  6 1 3  7 1 3>;
			};
		};

		/* SOCMEM SRAM MPC - large SoC memory */
		mpc_socmem: mpc@54642000 {
			compatible = "infineon,mxs40-mpc";
			reg = <0x54642000 0x1000>;
			violation-response = "bus-error";
			infineon,enable-socmem;
			#address-cells = <1>;
			#size-cells = <1>;
			status = "okay";

			/* M55: PC2/PC6/PC7 Non-Secure RW */
			region@0 {
				reg = <0x00000000 0x00040000>;
				pc-configs = <2 1 3  6 1 3  7 1 3>;
			};

			/* M33-M55 shared: PC2/PC5/PC6/PC7 Non-Secure RW */
			region@40000 {
				reg = <0x00040000 0x004C0000>;
				pc-configs = <2 1 3  5 1 3  6 1 3  7 1 3>;
			};
		};

		/*
		 * Peripheral Protection Controllers (PPC)
		 *
		 * nonsecure-regions lists the cy_en_prot_region_t region indices to
		 * open for NS access, mirroring the Infineon BSP / TF-M "M33_M55"
		 * non-secure PPC domain (pc-mask 0xE6, NON_SECURE/NONPRIV).  Only the
		 * console SCB path is opened; a full sweep bus-faults on
		 * self-protection / SROM-locked slots.
		 *
		 * The PROT_PERI*_* names come from <zephyr/dt-bindings/ppc/
		 * infineon-edge-ppc.h> (mirroring the HAL pse84_config.h enum).  A
		 * future enhancement could reference peripheral nodes directly
		 * (e.g. nonsecure-peripherals = <&scb2>) by giving each peripheral its
		 * PROT region and having the driver deref the phandles.
		 */

		/* PPC0 - PERI0 peripheral bus (MAIN, GR1..GR5, PCLK0, console SCB2). */
		ppc0: ppc@52020000 {
			compatible = "infineon,mxs40-ppc";
			reg = <0x52020000 0x2000>;
			nonsecure-regions = <PROT_PERI0_MAIN
					     PROT_PERI0_GR1_GROUP
					     PROT_PERI0_GR2_GROUP
					     PROT_PERI0_GR3_GROUP
					     PROT_PERI0_GR4_GROUP
					     PROT_PERI0_GR5_GROUP
					     PROT_PERI0_PERI_PCLK0_MAIN
					     PROT_PERI0_SCB2>;
			pc-mask = <0xE6>;
			status = "okay";
		};

		/* PPC1 - PERI1 peripheral bus. The console SCB is on PERI0/PPC0;
		 * PPC1 is left disabled until a peripheral there needs NS access.
		 * (PERI1 region indices are offset by 0x10000000, so PROT_PERI1_MAIN
		 * == 0x10000000 — see infineon-edge-ppc.h.)
		 */
		ppc1: ppc@54020000 {
			compatible = "infineon,mxs40-ppc";
			reg = <0x54020000 0x2000>;
			nonsecure-regions = <PROT_PERI1_MAIN>;
			pc-mask = <0xE6>;
			status = "disabled";
		};
	};
};
